# GD32F350 register map
File version: 1.0
CPU: CM4 r0p1, little endian, no MPU, FPU, 4 interrupt priority bits
Registers are 32-bit, read-write, reset 0x0 unless marked. A register's access mark holds for its fields unless they carry their own. Offsets are from the block's base; [hi:lo] are bit positions; lines under a group give offsets from that group; {n}, {i} and the like mark numbered series; 'fields as' and 'values as' point back to an identical list.

## TSI — Touch sensing Interface
Base 0x40024000
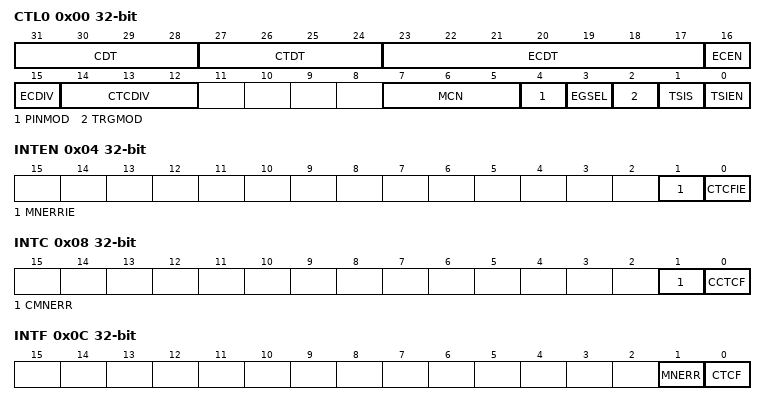
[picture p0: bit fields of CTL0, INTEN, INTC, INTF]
0x00 CTL0 — control register
  [31:28] CDT — Charge transfer pulse high
  [27:24] CTDT — Charge transfer pulse low
  [23:17] ECDT — Spread spectrum deviation
  [16] ECEN — Spread spectrum enable
  [15] ECDIV — Spread spectrum prescaler
  [14:12] CTCDIV — pulse generator prescaler
  [7:5] MCN — Max count value
  [4] PINMOD — I/O Default mode
  [3] EGSEL — Edge selection
  [2] TRGMOD — Trigger mode selection
  [1] TSIS — Start a new acquisition
  [0] TSIEN — Touch sensing controller enable
0x04 INTEN — interrupt enable register
  [1] MNERRIE — Max Cycle Number Error Interrupt Enable
  [0] CTCFIE — Charge-transfer complete flag Interrupt Enable
0x08 INTC — interrupt flag clear register
  [1] CMNERR — Clear max cycle number error
  [0] CCTCF — Clear charge-transfer complete flag
0x0C INTF — interrupt flag register
  [1] MNERR — Max count error flag
  [0] CTCF — End of acquisition flag
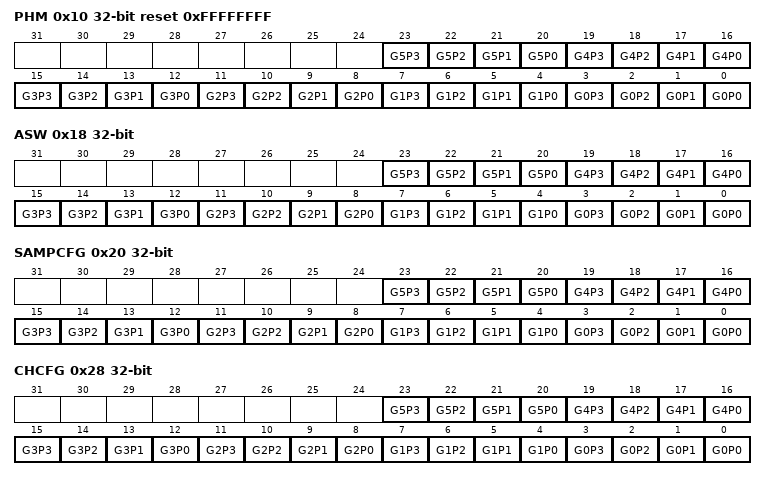
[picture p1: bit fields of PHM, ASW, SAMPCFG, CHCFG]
0x10 PHM reset 0xFFFFFFFF — Pin hysteresis mode register
  [4n+3] G{n}P3 (n=0..5) — G{n}P3 Schmitt trigger hysteresis mode
  [4n+2] G{n}P2 (n=0..5) — G{n}P2 Schmitt trigger hysteresis mode
  [4n+1] G{n}P1 (n=0..5) — G{n}P1 Schmitt trigger hysteresis mode
  [4n] G{n}P0 (n=0..5) — G{n}P0 Schmitt trigger hysteresis mode
0x18 ASW — I/O analog switch register
  [4n+3] G{n}P3 (n=0..5) — G{n}P3 analog switch enable
  [4n+2] G{n}P2 (n=0..5) — G{n}P2 analog switch enable
  [4n+1] G{n}P1 (n=0..5) — G{n}P1 analog switch enable
  [4n] G{n}P0 (n=0..5) — G{n}P0 analog switch enable
0x20 SAMPCFG — I/O sample configuration register
  [4n+3] G{n}P3 (n=0..5) — G{n}P3 sampling mode
  [4n+2] G{n}P2 (n=0..5) — G{n}P2 sampling mode
  [4n+1] G{n}P1 (n=0..5) — G{n}P1 sampling mode
  [4n] G{n}P0 (n=0..5) — G{n}P0 sampling mode
0x28 CHCFG — I/O channel configuration register
  [4n+3] G{n}P3 (n=0..5) — G{n}P3 channel mode
  [4n+2] G{n}P2 (n=0..5) — G{n}P2 channel mode
  [4n+1] G{n}P1 (n=0..5) — G{n}P1 channel mode
  [4n] G{n}P0 (n=0..5) — G{n}P0 channel mode
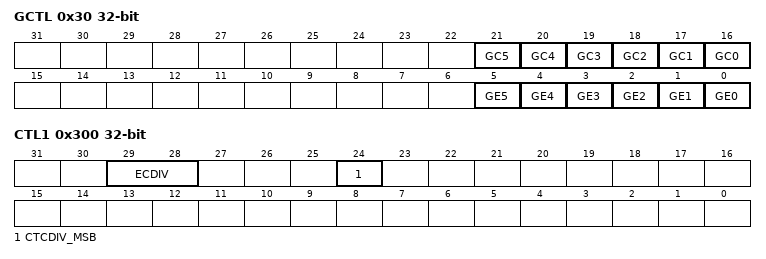
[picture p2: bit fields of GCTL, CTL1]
0x30 GCTL access per field — I/O group control register
  [n+16] GC{n} ro (n=0..5) — Analog I/O group x status
  [n] GE{n} rw (n=0..5) — Analog I/O group x enable
{0x34+4i} G{i}CYCN ro (i=0..5) — I/O group x cycle number register
  [13:0] CYCN — Cycle number
0x300 CTL1 write — control register 1
  [29:28] ECDIV — Extend Charge clock division factor
  [24] CTCDIV_MSB — Charge Transfer clock division factor

## USBFS_HOST — USB on the go full speed host
Base 0x50000400
0x00 HCTL — host configuration register (HCTL)
  [1:0] CLKSEL — clock select for USB clock
0x04 HFT reset 0xBB80 — Host frame interval register
  [15:0] FRI — Frame interval
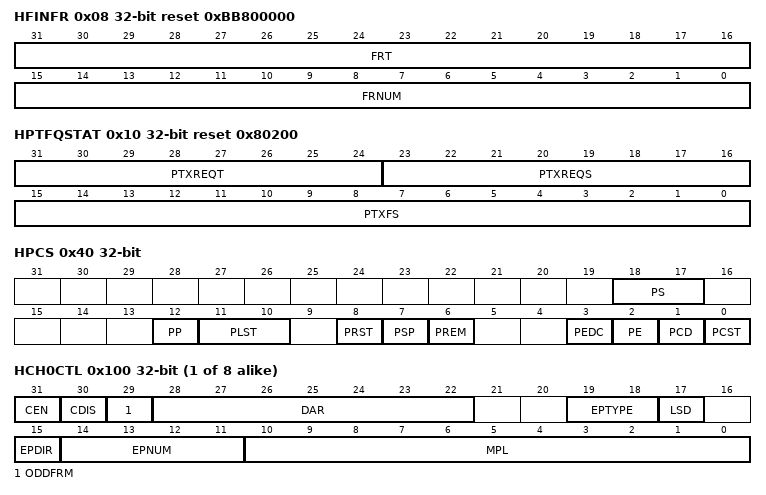
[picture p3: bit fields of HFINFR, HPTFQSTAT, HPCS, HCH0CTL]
0x08 HFINFR ro reset 0xBB800000 — OTG_FS host frame number/frame time remaining register (HFINFR)
  [31:16] FRT — Frame remaining time
  [15:0] FRNUM — Frame number
0x10 HPTFQSTAT ro reset 0x80200 — Host periodic transmit FIFO/queue status register (HPTFQSTAT)
  [31:24] PTXREQT — Top of the periodic transmit request queue
  [23:16] PTXREQS — Periodic transmit request queue space available
  [15:0] PTXFS — Periodic transmit data FIFO space available
0x14 HACHINT ro — Host all channels interrupt register
  [7:0] HACHINT — Host all channel interrupts
0x18 HACHINTEN — host all channels interrupt mask register
  [7:0] CINTEN — Channel interrupt enable
0x40 HPCS access per field — Host port control and status register (USBFS_HPCS)
  [18:17] PS ro — Port speed
  [12] PP rw — Port power
  [11:10] PLST ro — Port line status
  [8] PRST rw — Port reset
  [7] PSP rw — Port suspend
  [6] PREM rw — Port resume
  [3] PEDC rw — Port enable/disable change
  [2] PE rw — Port enable
  [1] PCD rw — Port connect detected
  [0] PCST ro — Port connect status
{0x100+0x20*i} HCH{i}CTL (i=0..7) — host channel-{i} characteristics register (HCH{i}CTL)
  [31] CEN — Channel enable
  [30] CDIS — Channel disable
  [29] ODDFRM — Odd frame
  [28:22] DAR — Device address
  [19:18] EPTYPE — Endpoint type
  [17] LSD — Low-speed device
  [15] EPDIR — Endpoint direction
  [14:11] EPNUM — Endpoint number
  [10:0] MPL — Maximum packet size
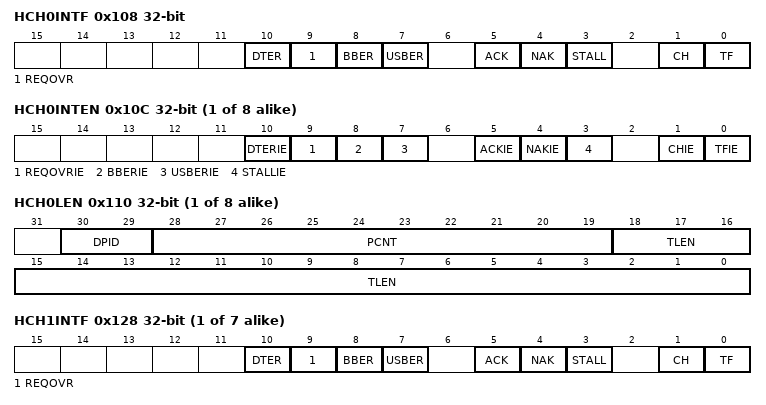
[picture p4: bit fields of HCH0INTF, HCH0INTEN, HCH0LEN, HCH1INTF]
0x108 HCH0INTF — host channel-0 interrupt register (USBFS_HCHxINTF)
  [10] DTER — Data toggle error
  [9] REQOVR — Request queue overrun
  [8] BBER — Babble error
  [7] USBER — USB bus error
  [5] ACK — ACK response received/transmitted interrupt
  [4] NAK — NAK response received interrupt
  [3] STALL — STALL response received interrupt
  [1] CH — Channel halted
  [0] TF — Transfer finished
{0x10C+0x20*i} HCH{i}INTEN (i=0..7) — host channel-{i} interrupt enable register (HCH{i}INTEN)
  [10] DTERIE — Data toggle error interrupt enable
  [9] REQOVRIE — request queue overrun interrupt enable
  [8] BBERIE — Babble error interrupt enable
  [7] USBERIE — USB bus error interrupt enable
  [5] ACKIE — ACK interrupt enable
  [4] NAKIE — NAK interrupt enable
  [3] STALLIE — STALL interrupt enable
  [1] CHIE — Channel halted interrupt enable
  [0] TFIE — Transfer completed interrupt enable
{0x110+0x20*i} HCH{i}LEN (i=0..7) — host channel-{i} transfer length register
  [30:29] DPID — Data PID
  [28:19] PCNT — Packet count
  [18:0] TLEN — Transfer length
{0x108+0x20*i} HCH{i}INTF (i=1..7) — host channel-{i} interrupt register (HCH{i}INTF)
  fields as HCH0INTF

## USBFS_PWRCLK — USB on the go full speed
Base 0x50000E00
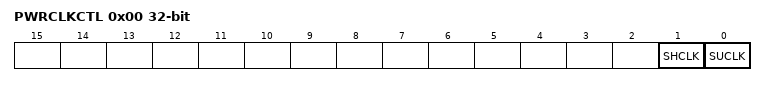
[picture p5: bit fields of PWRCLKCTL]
0x00 PWRCLKCTL — power and clock gating control register (PWRCLKCTL)
  [1] SHCLK — Stop HCLK
  [0] SUCLK — Stop the USB clock

## WWDGT — Window watchdog timer
Base 0x40002C00
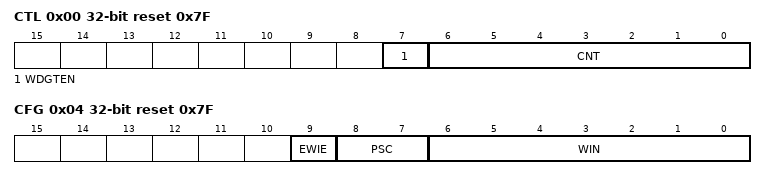
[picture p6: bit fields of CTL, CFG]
0x00 CTL reset 0x7F — Control register
  [7] WDGTEN — Activation bit
  [6:0] CNT — The value of the watchdog timer counter
0x04 CFG reset 0x7F — Configuration register
  [9] EWIE — Early wakeup interrupt
  [8:7] PSC — Prescaler
  [6:0] WIN — 7-bit window value
0x08 STAT — Status register
  [0] EWIF — Early wakeup interrupt flag
